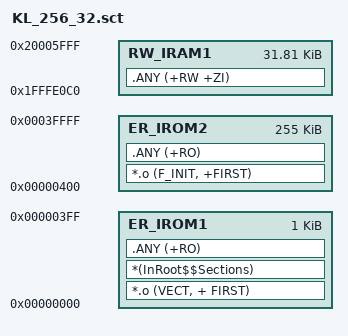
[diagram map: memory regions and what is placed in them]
;/* KL_256_32.ld                                                              */
;/* uVision memory file for the Kinetis KL - for use with the uTasker project */
;/* Use when running in FLASH (256k FLASH / 32k CPU SRAM)                     */

LR_IROM1 0x00000000 0x00000400  {    ; load region size_region
  ER_IROM1 0x00000000 0x00000400  {  ; load address = execution address
   *.o (VECT, + FIRST)
   *(InRoot$$Sections)
   .ANY (+RO)
  }
  RW_IRAM1 0x1FFFE0C0 0x00008000-0xC0  {  ; RW data
   .ANY (+RW +ZI)
  }
}

LR_IROM2 0x00000400 0x40000-0x400  {
  ER_IROM2 0x00000400 0x40000-0x400  {  ; load address = execution address
   *.o (F_INIT, +FIRST)
   .ANY (+RO)
  }
}
